AUTOSAR XML (schema 321)
package /ComponentType
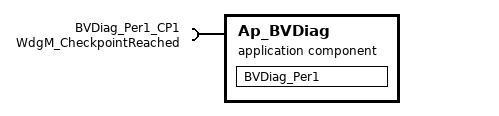
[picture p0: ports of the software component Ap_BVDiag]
  application software component type Ap_BVDiag
    require port BVDiag_Per1_CP1: client-com-spec=CheckpointReached, required-interface=WdgM_CheckpointReached
  internal behavior Ap_BVDiag_InternalBehavior: component=Ap_BVDiag, port-api-option{enable-take-address=false, indirect-api=false, port=BVDiag_Per1_CP1}
    runnable BVDiag_Per1
      sync call SC_BVDiag_Per1_CP1_CheckpointReached: operation=BVDiag_Per1_CP1.CheckpointReached, timeout=0
  swc implementation Ap_BVDiag_Implementation: behavior=Ap_BVDiag_InternalBehavior
    code-descriptors:
      code Code: type=SRC
package /PortInterface
  client server interface WdgM_CheckpointReached: is-service=true
    operation CheckpointReached: possible-error=E_NOT_OK  # Indicates to the Watchdog Manager that a Checkpoint within a Supervised Entity has been reached.
    error E_NOT_OK: error-code=1
